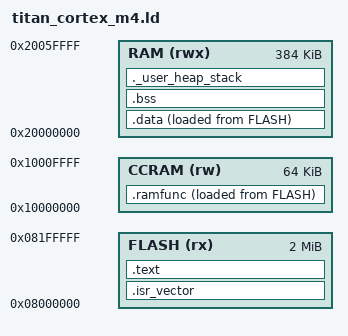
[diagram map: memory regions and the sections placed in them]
/* Linker script for ARM Cortex-M4 TitanCore-RT Target */
MEMORY
{
  FLASH (rx)      : ORIGIN = 0x08000000, LENGTH = 2048K
  RAM (rwx)       : ORIGIN = 0x20000000, LENGTH = 384K
  CCRAM (rw)      : ORIGIN = 0x10000000, LENGTH = 64K
}

ENTRY(Reset_Handler)

SECTIONS
{
  .isr_vector :
  {
    . = ALIGN(4);
    KEEP(*(.isr_vector))
    . = ALIGN(4);
  } > FLASH

  .text :
  {
    . = ALIGN(4);
    *(.text)
    *(.text*)
    *(.rodata)
    *(.rodata*)
    . = ALIGN(4);
    _etext = .;
  } > FLASH

  _sidata = LOADADDR(.data);

  .data :
  {
    . = ALIGN(4);
    _sdata = .;
    *(.data)
    *(.data*)
    . = ALIGN(4);
    _edata = .;
  } > RAM AT> FLASH

  .ramfunc :
  {
    . = ALIGN(4);
    *(.ramfunc)
    . = ALIGN(4);
  } > CCRAM AT> FLASH

  .bss :
  {
    . = ALIGN(4);
    _sbss = .;
    *(.bss)
    *(.bss*)
    *(COMMON)
    . = ALIGN(4);
    _ebss = .;
  } > RAM

  ._user_heap_stack :
  {
    . = ALIGN(8);
    PROVIDE ( end = . );
    PROVIDE ( _end = . );
    . = . + 0x4000; /* 16KB Stack */
    . = ALIGN(8);
  } > RAM
}
